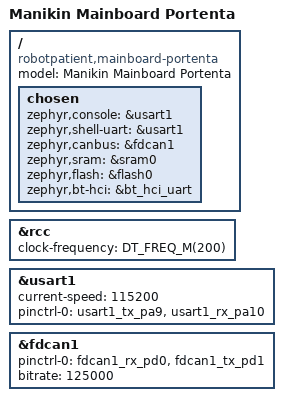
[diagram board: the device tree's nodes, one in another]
/*
 * Copyright (c) 2022 Benjamin Björnsson <benjamin.bjornsson@gmail.com>.
 *
 * SPDX-License-Identifier: Apache-2.0
 */

/dts-v1/;
#include <st/h7/stm32h747Xi_m4.dtsi>
#include <st/h7/stm32h747xihx-pinctrl.dtsi>
#include "manikin_mainboard_portenta-common.dtsi"

/ {
	model = "Manikin Mainboard Portenta";
	compatible = "robotpatient,mainboard-portenta";

	/* HW resources are split between CM7 and CM4 */

	chosen {
		zephyr,console = &usart1;
		zephyr,shell-uart = &usart1;
		zephyr,canbus = &fdcan1;
		zephyr,sram = &sram0;
		zephyr,flash = &flash0;
		zephyr,bt-hci = &bt_hci_uart;
	};
};

&rcc {
	clock-frequency = <DT_FREQ_M(200)>;
};

&usart1 {
    status = "okay";
    current-speed = <115200>;
    pinctrl-0 = <&usart1_tx_pa9 &usart1_rx_pa10>;
    pinctrl-names = "default";
};

&fdcan1 {
    status = "okay";
    pinctrl-0 = <&fdcan1_rx_pd0 &fdcan1_tx_pd1>;
    pinctrl-names = "default";
    /* Use 'bitrate' instead of 'bus-speed' */
    bitrate = <125000>;
};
